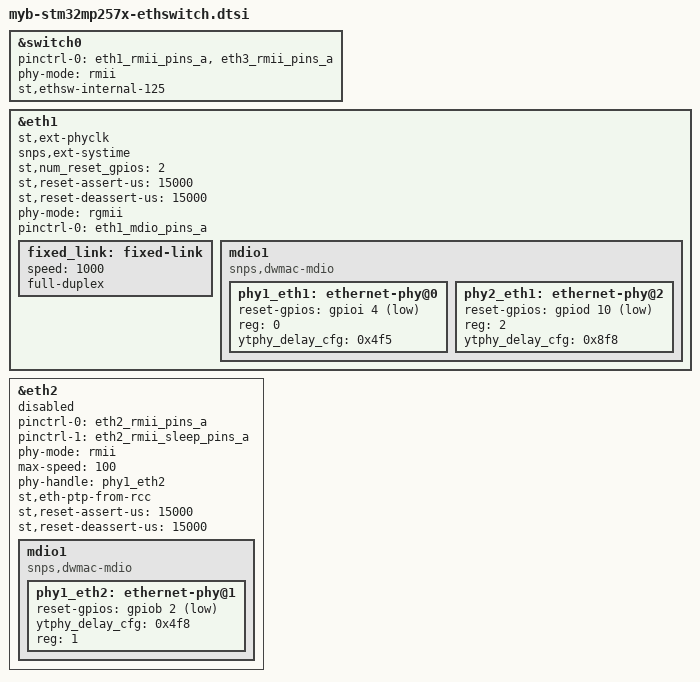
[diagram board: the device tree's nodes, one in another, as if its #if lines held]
// SPDX-License-Identifier: (GPL-2.0-only OR BSD-3-Clause)
/*
 * Copyright (C) MYiR 2024 - All Rights Reserved
 */


&switch0 {

#if (ETH_SWITCH_ENABLE)	
	status = "okay";
#else	
	status = "disabled";
#endif

	pinctrl-0 = <&eth1_rmii_pins_a>, <&eth3_rmii_pins_a>;
	pinctrl-names = "default";
	phy-mode = "rmii";
	st,ethsw-internal-125;
};

&eth1 {
	status = "okay";

	// max-speed = <100>;
	st,ext-phyclk;
	snps,ext-systime;

	st,num_reset_gpios = <2>;
	st,reset-assert-us = <15000>;
	st,reset-deassert-us = <15000>;

#if (ETH_SWITCH_ENABLE)	
	phy-mode = "rgmii";
	pinctrl-0 = <&eth1_mdio_pins_a>;
	pinctrl-names = "default";
	fixed_link: fixed-link {
		speed = <1000>;
		full-duplex;
	};
#else
	phy-mode = "rmii";
	pinctrl-0 = <&eth1_rmii_pins_a &eth1_mdio_pins_a>;
	pinctrl-1 = <&eth1_rmii_sleep_pins_a &eth1_mdio_sleep_pins_a>;
	pinctrl-names = "default", "sleep";
	phy-handle = <&phy1_eth1>;
#endif

	mdio1 {
		#address-cells = <1>;
		#size-cells = <0>;
		compatible = "snps,dwmac-mdio";

		phy1_eth1: ethernet-phy@0 {
			reset-gpios = <&gpioi 4 GPIO_ACTIVE_LOW>;
			reg = <0>;
			ytphy_delay_cfg = <0x4f5>;
		};

		phy2_eth1: ethernet-phy@2 {
			reset-gpios = <&gpiod 10 GPIO_ACTIVE_LOW>;
			reg = <2>;
			ytphy_delay_cfg = <0x8f8>;
		};
	};
};

&eth2 {
	status = "disabled";
	pinctrl-0 = <&eth2_rmii_pins_a>;
	pinctrl-1 = <&eth2_rmii_sleep_pins_a>;
	pinctrl-names = "default", "sleep";
	phy-mode = "rmii";
	max-speed = <100>;
	phy-handle = <&phy1_eth2>;
	st,eth-ptp-from-rcc;
	//st,ext-phyclk;

	st,reset-assert-us = <15000>;
	st,reset-deassert-us = <15000>;

	mdio1 {
		#address-cells = <1>;
		#size-cells = <0>;
		compatible = "snps,dwmac-mdio";
		phy1_eth2: ethernet-phy@1 {
			reset-gpios =  <&gpiob 2 GPIO_ACTIVE_LOW>;
			ytphy_delay_cfg = <0x4f8>;
			reg = <1>;
		};
	};
};

